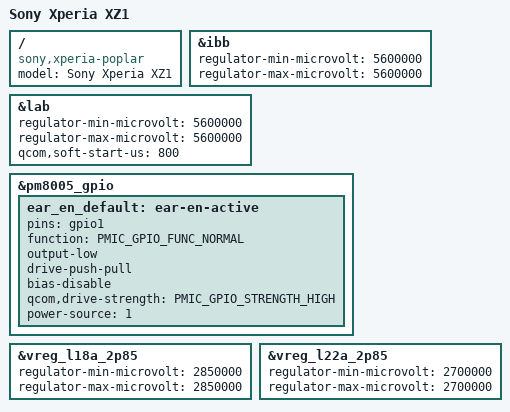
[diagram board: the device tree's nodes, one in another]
// SPDX-License-Identifier: BSD-3-Clause
/*
 * Copyright (c) 2021, AngeloGioacchino Del Regno
 *                     <angelogioacchino.delregno@somainline.org>
 */

/dts-v1/;

#include "msm8998-sony-xperia-yoshino.dtsi"

/ {
	model = "Sony Xperia XZ1";
	compatible = "sony,xperia-poplar", "qcom,msm8998";
};

&ibb {
	regulator-min-microvolt = <5600000>;
	regulator-max-microvolt = <5600000>;
};

&lab {
	regulator-min-microvolt = <5600000>;
	regulator-max-microvolt = <5600000>;
	qcom,soft-start-us = <800>;
};

&pm8005_gpio {
	ear_en_default: ear-en-active {
		pins = "gpio1";
		function = PMIC_GPIO_FUNC_NORMAL;
		output-low;
		drive-push-pull;
		bias-disable;
		qcom,drive-strength = <PMIC_GPIO_STRENGTH_HIGH>;
		power-source = <1>;
	};
};

&vreg_l18a_2p85 {
	regulator-min-microvolt = <2850000>;
	regulator-max-microvolt = <2850000>;
};

&vreg_l22a_2p85 {
	regulator-min-microvolt = <2700000>;
	regulator-max-microvolt = <2700000>;
};
